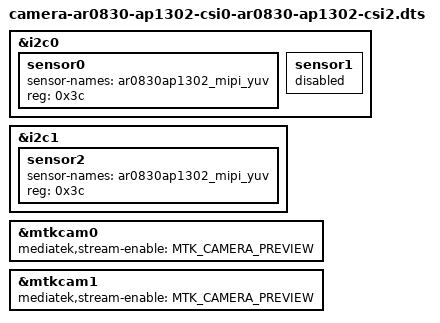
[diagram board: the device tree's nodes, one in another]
// SPDX-License-Identifier: GPL-2.0
/*
 * Copyright (c) 2024 MediaTek Inc.
 *
 */

/dts-v1/;
/plugin/;

#include "camera-common.dtsi"

/ {
	fragment@10 {
		target = <&i2c0>;
		__overlay__ {
			sensor0 {
				sensor-names = "ar0830ap1302_mipi_yuv";
				reg = <0x3c>;
				status = "okay";
			};
			sensor1 {
				status = "disabled";
			};
		};
	};

	fragment@11 {
		target = <&i2c1>;
		__overlay__ {
			sensor2 {
				sensor-names = "ar0830ap1302_mipi_yuv";
				reg = <0x3c>;
				status = "okay";
			};
		};
	};

	fragment@12 {
		target = <&mtkcam0>;
		__overlay__ {
			status = "okay";
			mediatek,stream-enable = <MTK_CAMERA_PREVIEW>;
		};
	};

	fragment@13 {
		target = <&mtkcam1>;
		__overlay__ {
			status = "okay";
			mediatek,stream-enable = <MTK_CAMERA_PREVIEW>;
		};
	};
};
